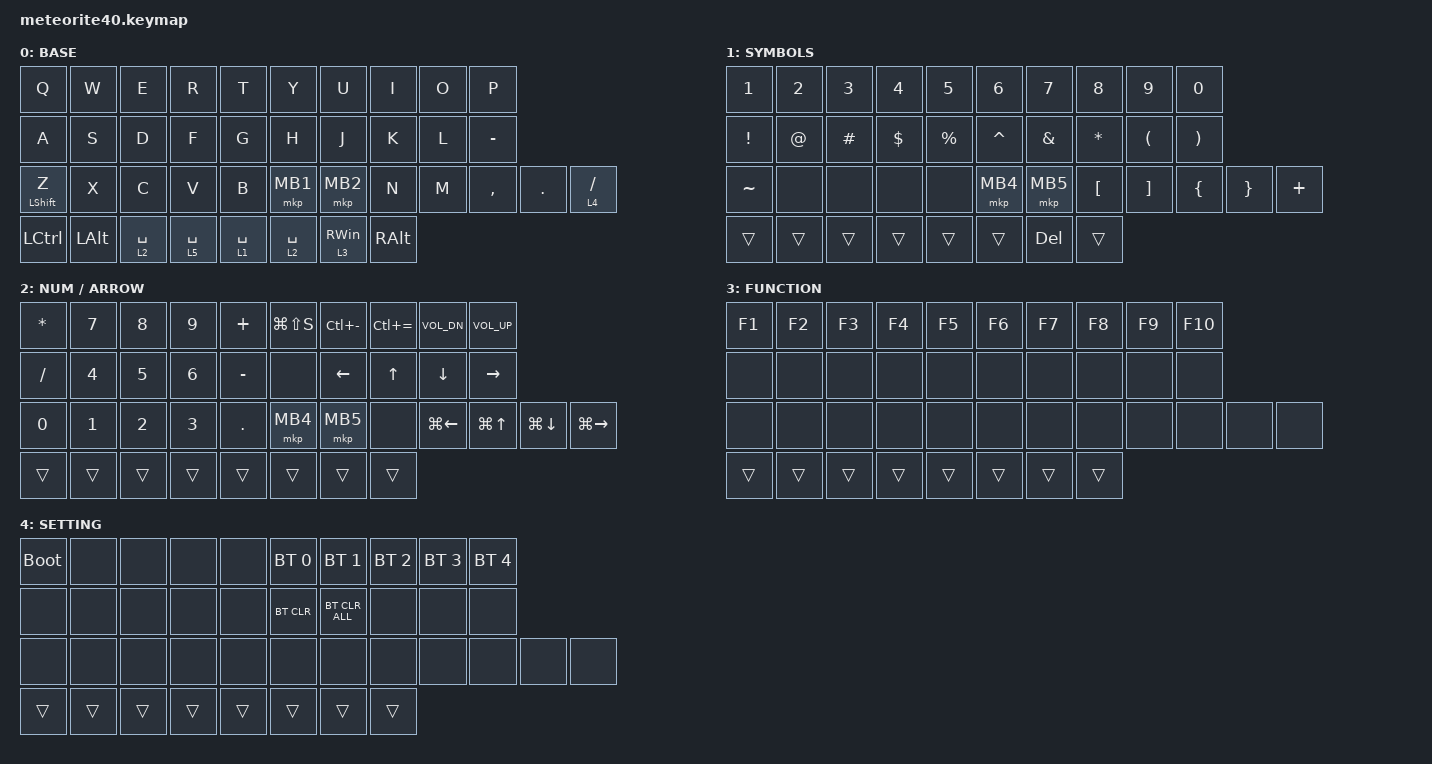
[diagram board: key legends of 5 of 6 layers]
#include <behaviors.dtsi>
#include <dt-bindings/zmk/bt.h>
#include <dt-bindings/zmk/keys.h>
#include <dt-bindings/zmk/pointing.h>

&mt {
    flavor = "tap-preferred";
    tapping-term-ms = <200>;
    quick-tap-ms = <150>;
};

&lt {
    flavor = "tap-preferred";
    tapping-term-ms = <150>;
    quick-tap-ms = <150>;
};

/ {

    combos {
        compatible = "zmk,combos";

        // Navigation combos
        tab {
            bindings = <&kp TAB>;
            key-positions = <11 10>;
        };

        enter_combo {
            bindings = <&kp ENTER>;
            key-positions = <18 19>;
        };

        // Punctuation combos
        equals {
            bindings = <&kp EQUAL>;
            key-positions = <8 9>;
        };

        escape {
            bindings = <&kp ESCAPE>;
            key-positions = <1 0>;
        };

        // Letter combos
        shift_z {
            bindings = <&kp LS(Z)>;
            key-positions = <20 21>;
        };

        question_mark {
            bindings = <&kp RS(SLASH)>;
            key-positions = <31 30>;
        };

        bs {
            bindings = <&kp BSPC>;
            key-positions = <9 8>;
        };
    };

    keymap {
        compatible = "zmk,keymap";
        layout = &LAYOUT_2U_SPACE;

        win_default_layer {
            display-name = "BASE";
            bindings = <
                &kp Q          &kp W          &kp E          &kp R          &kp T          &kp Y          &kp U          &kp I          &kp O          &kp P
                &kp A          &kp S          &kp D          &kp F          &kp G          &kp H          &kp J          &kp K          &kp L          &kp MINUS
                &mt LSHIFT Z   &kp X          &kp C          &kp V          &kp B          &mkp MB1       &mkp MB2       &kp N          &kp M          &kp COMMA     &kp DOT     &lt 4 SLASH
                &kp LCTRL      &kp LEFT_ALT   &lt 2 SPACE    &lt 5 SPACE    &lt 1 SPACE    &lt 2 SPACE    &lt 3 RIGHT_WIN &kp RALT
            >;

            sensor-bindings =
                <&inc_dec_kp LC(MINUS) LC(EQUAL)>,
                <&inc_dec_kp C_VOL_DN C_VOL_UP>;
        };

        layer_1 {
            display-name = "SYMBOLS";
            bindings = <
                &kp NUMBER_1          &kp NUMBER_2          &kp NUMBER_3          &kp NUMBER_4          &kp NUMBER_5          &kp NUMBER_6          &kp NUMBER_7          &kp NUMBER_8          &kp NUMBER_9          &kp NUMBER_0
                &kp EXCLAMATION       &kp AT_SIGN           &kp HASH              &kp DOLLAR            &kp PERCENT           &kp CARET             &kp AMPERSAND         &kp ASTERISK          &kp LEFT_PARENTHESIS  &kp RIGHT_PARENTHESIS
                &kp TILDE             &none                 &none                 &none                 &none                 &mkp MB4              &mkp MB5              &kp LEFT_BRACKET      &kp RIGHT_BRACKET     &kp LBRC              &kp RBRC              &kp PLUS
                &trans                &trans                &trans                &trans                &trans                &trans                &kp DEL               &trans
            >;

            sensor-bindings =
                <&inc_dec_kp LC(MINUS) LC(EQUAL)>,
                <&inc_dec_kp C_VOL_DN C_VOL_UP>;
        };

        layer_2 {
            display-name = "NUM / ARROW";
            bindings = <
                &kp ASTRK      &kp N7          &kp N8          &kp N9          &kp PLUS          &kp LG(LS(S))    &kp LC(MINUS)    &kp LC(EQUAL)    &kp C_VOL_DN    &kp C_VOL_UP
                &kp SLASH      &kp N4          &kp N5          &kp N6          &kp MINUS         &none             &kp LEFT         &kp UP           &kp DOWN        &kp RIGHT
                &kp N0         &kp N1          &kp N2          &kp N3          &kp DOT           &mkp MB4          &mkp MB5         &none            &kp LG(LEFT)    &kp LG(UP)      &kp LG(DOWN)    &kp LG(RIGHT)
                &trans         &trans          &trans          &trans          &trans            &trans            &trans           &trans
            >;

            sensor-bindings =
                <&inc_dec_kp LC(MINUS) LC(EQUAL)>,
                <&inc_dec_kp C_VOL_DN C_VOL_UP>;
        };

        layer_3 {
            display-name = "FUNCTION";
            bindings = <
                &kp F1         &kp F2          &kp F3          &kp F4          &kp F5          &kp F6          &kp F7          &kp F8          &kp F9          &kp F10
                &none          &none           &none           &none           &none           &none           &none           &none           &none           &none
                &none          &none           &none           &none           &none           &none           &none           &none           &none           &none           &none           &none
                &trans         &trans          &trans          &trans          &trans          &trans          &trans          &trans
            >;

            sensor-bindings =
                <&inc_dec_kp LC(MINUS) LC(EQUAL)>,
                <&inc_dec_kp C_VOL_DN C_VOL_UP>;
        };

        layer_4 {
            display-name = "SETTING";
            bindings = <
                &bootloader    &none           &none           &none           &none           &bt BT_SEL 0     &bt BT_SEL 1     &bt BT_SEL 2     &bt BT_SEL 3     &bt BT_SEL 4
                &none          &none           &none           &none           &none           &bt BT_CLR       &bt BT_CLR_ALL   &none            &none            &none
                &none          &none           &none           &none           &none           &none            &none            &none            &none            &none            &none            &none
                &trans         &trans          &trans          &trans          &trans          &trans           &trans           &trans
            >;

            sensor-bindings =
                <&inc_dec_kp LC(MINUS) LC(EQUAL)>,
                <&inc_dec_kp C_VOL_DN C_VOL_UP>;
        };

        layer_5 {
            display-name = "SCROLL";
            bindings = <
                &kp F1         &kp F2          &kp F3          &kp F4          &kp F5          &kp F6           &kp F7           &kp F8           &kp F9           &kp F10
                &kp F11        &kp F12         &none           &none           &none           &none            &none            &none            &none            &none
                &none          &none           &none           &none           &none           &mkp MB1         &mkp MB2         &kp LEFT         &kp UP           &kp DOWN         &kp RIGHT
                &trans         &trans          &trans          &trans          &trans          &trans           &trans           &trans
            >;

            sensor-bindings =
                <&inc_dec_kp LC(MINUS) LC(EQUAL)>,
                <&inc_dec_kp C_VOL_DN C_VOL_UP>;
        };
    };
};
